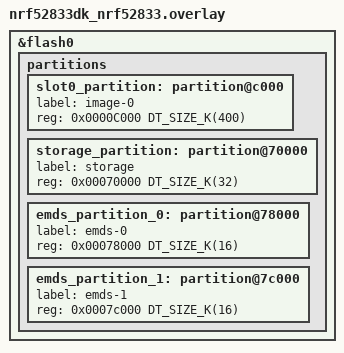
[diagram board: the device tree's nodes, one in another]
/delete-node/ &slot0_partition;
/delete-node/ &slot1_partition;
/delete-node/ &storage_partition;

&flash0 {
	partitions {
		slot0_partition: partition@c000 {
			label = "image-0";
			reg = <0x0000C000 DT_SIZE_K(400)>;
		};

		storage_partition: partition@70000 {
			label = "storage";
			reg = <0x00070000 DT_SIZE_K(32)>;
		};

		emds_partition_0: partition@78000 {
			label = "emds-0";
			reg = <0x00078000 DT_SIZE_K(16)>;
		};

		emds_partition_1: partition@7c000 {
			label = "emds-1";
			reg = <0x0007c000 DT_SIZE_K(16)>;
		};
	};
};
